# max32630 register map
Vendor: Maxim Integrated; Series: max3263x; File version: 1.2
CPU: CM4 r0p1, little endian, no MPU, FPU, 3 interrupt priority bits
Registers are 32-bit, read-write, reset 0x0 unless marked. A register's access mark holds for its fields unless they carry their own. Offsets are from the block's base; [hi:lo] are bit positions; {n}, {i} and the like mark numbered series.

## FLC — Flash Controller
Base 0x40002000
0x00 FADDR — Flash Operation Address
  [21:0] faddr
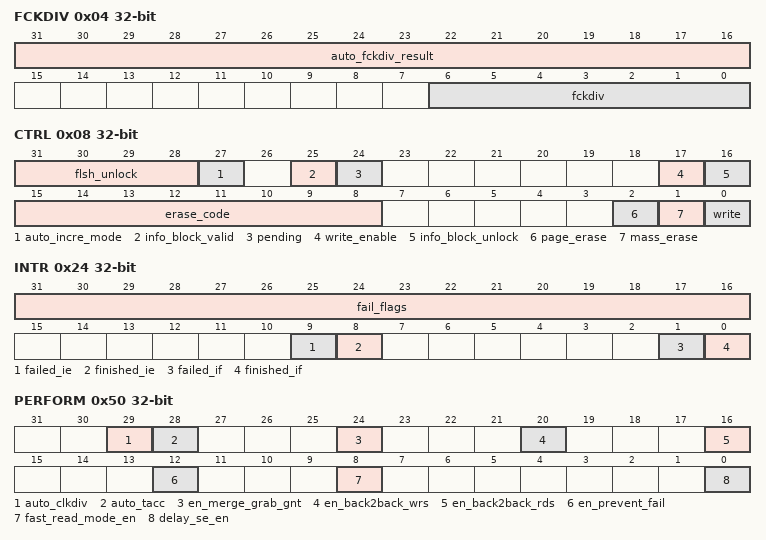
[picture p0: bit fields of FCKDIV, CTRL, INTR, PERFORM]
0x04 FCKDIV — Flash Clock Pulse Divisor
  [31:16] auto_fckdiv_result ro — Auto FCKDIV Calculation Result
  [6:0] fckdiv — Flash Clock Pulse Divisor
0x08 CTRL — Flash Control Register
  [31:28] flsh_unlock — Flash Write/Erase Enable
  [27] auto_incre_mode — Address Auto-Increment Mode
  [25] info_block_valid ro — Info Block Valid Status
  [24] pending ro — Flash Controller Status
  [17] write_enable ro — Flash Writes Enabled
  [16] info_block_unlock ro — Flash Info Block Locked
  [15:8] erase_code — Flash Erase Code
  [2] page_erase — Start Flash Page Erase Operation
  [1] mass_erase — Start Flash Mass Erase Operation
  [0] write — Start Flash Write Operation
0x24 INTR — Flash Controller Interrupt Flags and Enable/Disable 0
  [31:16] fail_flags ro — Flash Operation Failure Details
  [9] failed_ie — Flash Operation Failed Interrupt Enable
  [8] finished_ie — Flash Write/Erase Operation Finished Interrupt Enable
  [1] failed_if — Flash Operation Failed
  [0] finished_if — Flash Write/Erase Operation Finished
0x30 FDATA — Flash Operation Data Register
0x50 PERFORM — Flash Performance Settings
  [29] auto_clkdiv
  [28] auto_tacc
  [24] en_merge_grab_gnt — Enable Merge Grab GNT
  [20] en_back2back_wrs — Enable Back To Back Writes
  [16] en_back2back_rds — Enable Back To Back Reads
  [12] en_prevent_fail — Prevent Fail Flag Set on FLC Busy
  [8] fast_read_mode_en — Fast Read Mode Enable (Deprecated)
  [0] delay_se_en — Delay SE Enable (Deprecated)
0x54 TACC — Flash Read Cycle Config
0x58 TPROG — Flash Write Cycle Config
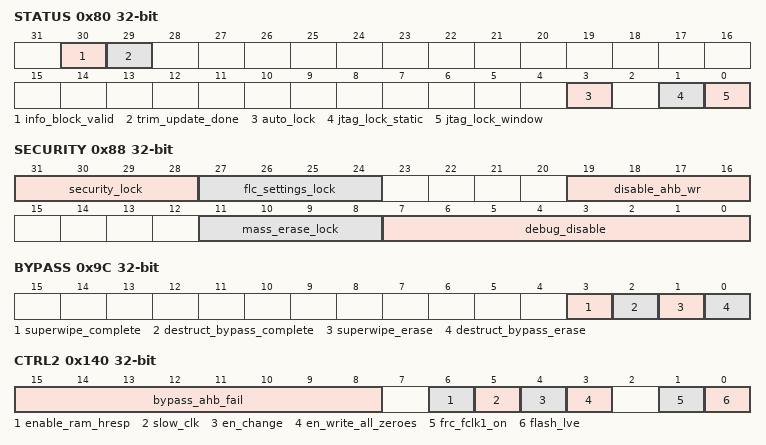
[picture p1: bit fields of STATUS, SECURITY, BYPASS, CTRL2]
0x80 STATUS — Security Status Flags
  [30] info_block_valid ro
  [29] trim_update_done ro
  [3] auto_lock ro — Debug Locked - Auto Lock
  [1] jtag_lock_static ro — Debug Locked - Firmware Lockout
  [0] jtag_lock_window ro — Debug Locked - Hardware Window
0x88 SECURITY — Flash Controller Security Settings
  [31:28] security_lock
  [27:24] flc_settings_lock
  [19:16] disable_ahb_wr — Disable AHB Flash Write Operations
  [11:8] mass_erase_lock — Mass Erase Lockout
  [7:0] debug_disable — Debug Lockout
0x9C BYPASS — Status Flags for DSB Operations
  [3] superwipe_complete ro — Superwipe Erase Complete
  [2] destruct_bypass_complete ro — Destructive Security Bypass Erase Complete
  [1] superwipe_erase ro — Superwipe Erase In Progress
  [0] destruct_bypass_erase ro — Destructive Security Bypass In Progress
0x100 USER_OPTION — Used to set DSB Access code and Auto-Lock in info block
0x140 CTRL2 — Flash Control Register 2
  [15:8] bypass_ahb_fail — AHB Fail Bypass
  [6] enable_ram_hresp
  [5] slow_clk ro — Clock Too Slow Status
  [4] en_change — Enable FLC Register Changes
  [3] en_write_all_zeroes — Enable Write All Zeroes
  [1] frc_fclk1_on — Force FCLK1 On
  [0] flash_lve — Flash LVE Enable
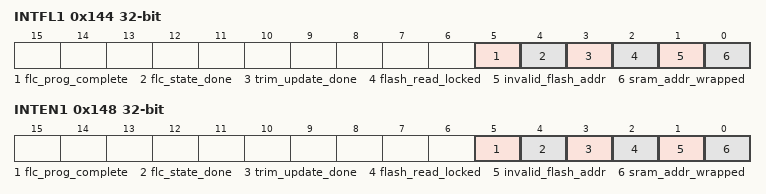
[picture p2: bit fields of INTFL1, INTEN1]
0x144 INTFL1 — Interrupt Flags Register 1
  [5] flc_prog_complete write-1-clears — Program (Write or Erase) Operation Completed Interrupt Flag
  [4] flc_state_done write-1-clears — FLC State Machine Reached DONE Interrupt Flag
  [3] trim_update_done write-1-clears — Trim Update Complete Interrupt Flag
  [2] flash_read_locked write-1-clears — Flash Read from Locked Area Interrupt Flag
  [1] invalid_flash_addr write-1-clears — Invalid Flash Address Interrupt Flag
  [0] sram_addr_wrapped write-1-clears — SRAM Address Wrapped Interrupt Flag
0x148 INTEN1 — Interrupt Enable/Disable Register 1
  [5] flc_prog_complete — Program (Write or Erase) Op Completed Int Enable/Disable
  [4] flc_state_done — FLC State Machine Reached DONE Interrupt Enable/Disable
  [3] trim_update_done — Trim Update Complete Interrupt Enable/Disable
  [2] flash_read_locked — Flash Read from Locked Area Interrupt Enable/Disable
  [1] invalid_flash_addr — Invalid Flash Address Interrupt Enable/Disable
  [0] sram_addr_wrapped — SRAM Address Wrapped Interrupt Enable/Disable
0x170 BL_CTRL — Bootloader Control Register
0x174 TWK — FLC TWK Cycle Count
0x17C SLM — Sleep Mode Register
{0x200+4i} DISABLE_XR{i} (i=0..7) — Disable Flash Page Exec/Read Register {i}
{0x300+4i} DISABLE_WE{i} (i=0..7) — Disable Flash Page Write/Erase Register {i}
